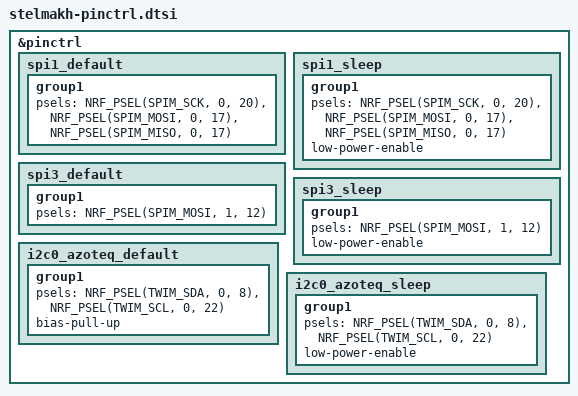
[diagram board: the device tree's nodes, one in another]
&pinctrl {
    
    spi1_default: spi1_default {
        group1 {
            psels = <NRF_PSEL(SPIM_SCK, 0, 20)>,
                <NRF_PSEL(SPIM_MOSI, 0, 17)>,
                <NRF_PSEL(SPIM_MISO, 0, 17)>;
        };
    };
    spi1_sleep: spi1_sleep {
        group1 {
            psels = <NRF_PSEL(SPIM_SCK, 0, 20)>,
                <NRF_PSEL(SPIM_MOSI, 0, 17)>,
                <NRF_PSEL(SPIM_MISO, 0, 17)>;
            low-power-enable;
        };
    };

    spi3_default: spi3_default {
        group1 {
            psels = <NRF_PSEL(SPIM_MOSI, 1, 12)>; // WS2812_VEXT_DATA - old (SPIM_MOSI, 0, 6)
        };
    };

    spi3_sleep: spi3_sleep {
        group1 {
            psels = <NRF_PSEL(SPIM_MOSI, 1, 12)>;
            low-power-enable;
        };
    };
    
    i2c0_azoteq_default: i2c0_azoteq_default {
        group1 {
            psels = <NRF_PSEL(TWIM_SDA, 0, 8)>,    // P0.08 (D1)
                    <NRF_PSEL(TWIM_SCL, 0, 22)>;   // P0.22 (D4)
            bias-pull-up;  // Enable internal pull-up resistors for I2C
        };
    };

    i2c0_azoteq_sleep: i2c0_azoteq_sleep {
        group1 {
            psels = <NRF_PSEL(TWIM_SDA, 0, 8)>,    
                    <NRF_PSEL(TWIM_SCL, 0, 22)>;   
            low-power-enable;
        };
    };
};
